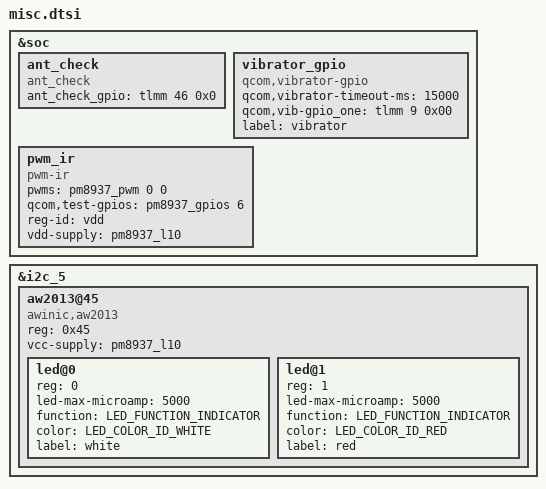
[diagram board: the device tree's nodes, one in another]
/*
 * Copyright (c) 2015-2016, The Linux Foundation. All rights reserved.
 * Copyright (C) 2018 XiaoMi, Inc.
 *
 * This program is free software; you can redistribute it and/or modify
 * it under the terms of the GNU General Public License version 2 and
 * only version 2 as published by the Free Software Foundation.
 *
 * This program is distributed in the hope that it will be useful,
 * but WITHOUT ANY WARRANTY; without even the implied warranty of
 * MERCHANTABILITY or FITNESS FOR A PARTICULAR PURPOSE.  See the
 * GNU General Public License for more details.
 */

#include <dt-bindings/leds/common.h>

&soc {
	ant_check {
		compatible = "ant_check";
		ant_check_gpio = <&tlmm 46 0x0>;
	};

	vibrator_gpio {
		compatible = "qcom,vibrator-gpio";
		qcom,vibrator-timeout-ms = <15000>;
		qcom,vib-gpio_one = <&tlmm 9 0x00>;
		label = "vibrator";
	};

	pwm_ir {
		compatible = "pwm-ir";
		pwms = <&pm8937_pwm 0 0>;
		qcom,test-gpios = <&pm8937_gpios 6 0>;
		reg-id = "vdd";
		vdd-supply = <&pm8937_l10>;
	};
};

&i2c_5 {
	aw2013@45 {
		#address-cells = <1>;
		#size-cells = <0>;

		compatible = "awinic,aw2013";

		reg = <0x45>;
		vcc-supply = <&pm8937_l10>;

		led@0 {
			reg = <0>;
			led-max-microamp = <5000>;
			function = LED_FUNCTION_INDICATOR;
			color = <LED_COLOR_ID_WHITE>;
			label = "white";
		};
		led@1 {
			reg = <1>;
			led-max-microamp = <5000>;
			function = LED_FUNCTION_INDICATOR;
			color = <LED_COLOR_ID_RED>;
			label = "red";
		};
	};
};
